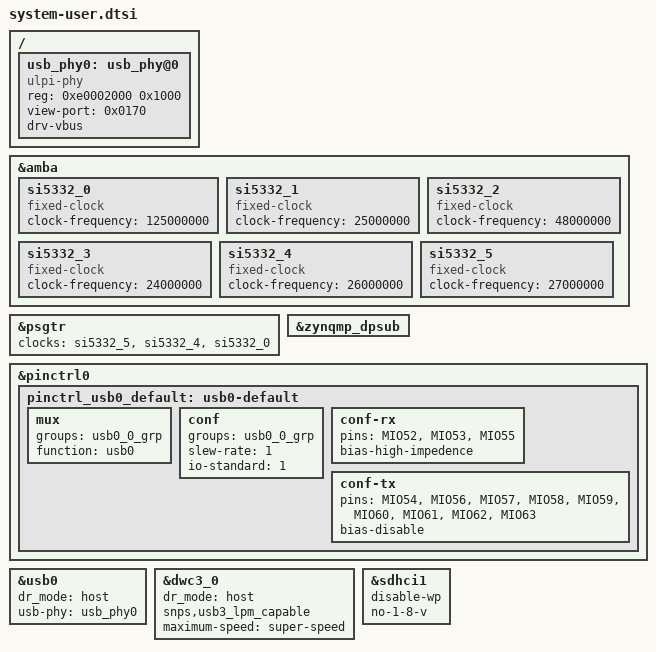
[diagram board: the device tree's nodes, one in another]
/include/ "system-conf.dtsi"

&amba {
	si5332_0: si5332_0 { /* u17 */
		compatible = "fixed-clock";
		#clock-cells = <0>;
		clock-frequency = <125000000>;
	};

	si5332_1: si5332_1 { /* u17 */
		compatible = "fixed-clock";
		#clock-cells = <0>;
		clock-frequency = <25000000>;
	};

	si5332_2: si5332_2 { /* u17 */
		compatible = "fixed-clock";
		#clock-cells = <0>;
		clock-frequency = <48000000>;
	};

	si5332_3: si5332_3 { /* u17 */
		compatible = "fixed-clock";
		#clock-cells = <0>;
		clock-frequency = <24000000>;
	};

	si5332_4: si5332_4 { /* u17 */
		compatible = "fixed-clock";
		#clock-cells = <0>;
		clock-frequency = <26000000>;
	};

	si5332_5: si5332_5 { /* u17 */
		compatible = "fixed-clock";
		#clock-cells = <0>;
		clock-frequency = <27000000>;
	};
};

&psgtr {
	status = "okay";
	clocks = <&si5332_5>, <&si5332_4>, <&si5332_0>;
	clock-names = "ref0", "ref1", "ref2";
};

&zynqmp_dpsub {
	status = "okay";
};


&pinctrl0 { /* required by spec */
        pinctrl_usb0_default: usb0-default {
		mux {
			groups = "usb0_0_grp";
			function = "usb0";
		};
		
		conf {
			groups = "usb0_0_grp";
			slew-rate = <1>;
			io-standard = <1>;
		};
		
		conf-rx {
			pins = "MIO52", "MIO53", "MIO55";
			bias-high-impedence;
		};
		
		conf-tx {
			pins = "MIO54", "MIO56", "MIO57", "MIO58", "MIO59", "MIO60", "MIO61", "MIO62", "MIO63";
			bias-disable;
		};
		
	};
};
/{
	usb_phy0: usb_phy@0 {
		compatible = "ulpi-phy";
		#phy-cells = <0>;
		reg = <0xe0002000 0x1000>;
		view-port = <0x0170>;
		drv-vbus;
	};
};

&usb0 {
	dr_mode = "host";
	status = "okay";
	usb-phy = <&usb_phy0>;
};

&dwc3_0 {
	dr_mode = "host";
	snps,usb3_lpm_capable;
	phy-names = "usb3-phy";
	maximum-speed = "super-speed";
};

&sdhci1 {
	disable-wp; 
	no-1-8-v;
};
